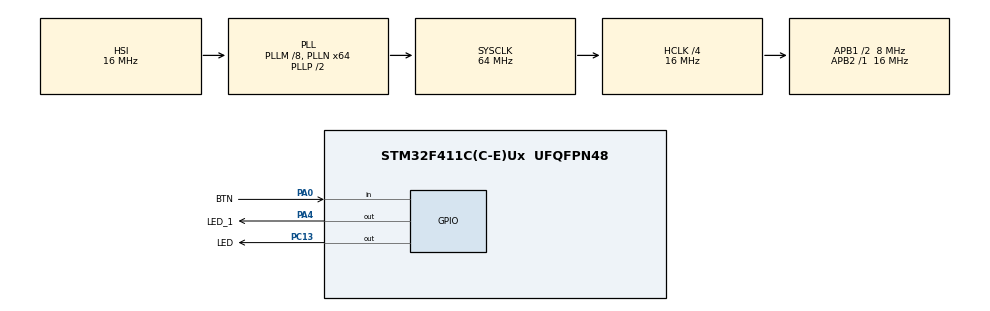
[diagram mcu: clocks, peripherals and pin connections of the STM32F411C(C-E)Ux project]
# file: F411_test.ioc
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Mcu.Family=STM32F4
Mcu.Name=STM32F411C(C-E)Ux
Mcu.Package=UFQFPN48
NVIC.PriorityGroup=NVIC_PRIORITYGROUP_4
PA0-WKUP.GPIO_Label=BTN
PA0-WKUP.GPIO_PuPd=GPIO_PULLUP
PA0-WKUP.Signal=GPIO_Input
PA4.GPIO_Label=LED_1
PA4.Signal=GPIO_Output
PC13-ANTI_TAMP.GPIO_Label=LED
PC13-ANTI_TAMP.PinState=GPIO_PIN_SET
PC13-ANTI_TAMP.Signal=GPIO_Output
ProjectManager.HeapSize=0x200
ProjectManager.StackSize=0x400
ProjectManager.TargetToolchain=STM32CubeIDE
RCC.48MHZClocksFreq_Value=32000000
RCC.AHBCLKDivider=RCC_SYSCLK_DIV4
RCC.AHBFreq_Value=16000000
RCC.APB1CLKDivider=RCC_HCLK_DIV2
RCC.APB1Freq_Value=8000000
RCC.APB1TimFreq_Value=16000000
RCC.APB2Freq_Value=16000000
RCC.APB2TimFreq_Value=16000000
RCC.CortexFreq_Value=16000000
RCC.HCLKFreq_Value=16000000
RCC.HSE_VALUE=25000000
RCC.HSI_VALUE=16000000
RCC.LSE_VALUE=32768
RCC.PLLM=8
RCC.PLLN=64
RCC.SYSCLKFreq_VALUE=64000000
RCC.SYSCLKSource=RCC_SYSCLKSOURCE_PLLCLK
RCC.VCOOutputFreq_Value=128000000
board=custom

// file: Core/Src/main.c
/* USER CODE BEGIN Header */
/**
  ******************************************************************************
  * @file           : main.c
  * @brief          : Main program body
  ******************************************************************************
  * @attention
  *
  * Copyright (c) 2026 STMicroelectronics.
  * All rights reserved.
  *
  * This software is licensed under terms that can be found in the LICENSE file
  * in the root directory of this software component.
  * If no LICENSE file comes with this software, it is provided AS-IS.
  *
  ******************************************************************************
  */
/* USER CODE END Header */
#include "main.h"

/* USER CODE BEGIN Includes */
#include <stdbool.h>
/* USER CODE END Includes */

/* USER CODE BEGIN PV */
static GPIO_PinState lastRaw;
static GPIO_PinState stable;
static uint32_t changedAt;
static bool state;
/* USER CODE END PV */

void SystemClock_Config(void);
static void MX_GPIO_Init(void);

int main(void)
{

  /* MCU Configuration--------------------------------------------------------*/

  /* Reset of all peripherals, Initializes the Flash interface and the Systick. */
  HAL_Init();

  /* Configure the system clock */
  SystemClock_Config();

  /* Initialize all configured peripherals */
  MX_GPIO_Init();
  /* USER CODE BEGIN 2 */
  lastRaw = HAL_GPIO_ReadPin(BTN_GPIO_Port, BTN_Pin);
  stable = lastRaw;
  changedAt = HAL_GetTick();
  state = false;
  /* USER CODE END 2 */

  /* Infinite loop */
  while (1)
  {

    /* USER CODE BEGIN 3 */

	  const uint32_t now = HAL_GetTick();
	      const GPIO_PinState raw = HAL_GPIO_ReadPin(BTN_GPIO_Port, BTN_Pin);
	      if (raw != lastRaw) {
	        lastRaw = raw;
	        changedAt = now;
	      }
	      if ((raw != stable) && ((uint32_t)(now - changedAt) >= 30U)) {
	        stable = raw;
	        if (stable == GPIO_PIN_RESET) {
	          state = !state;
	          /* LED_1_Pin - A4 */
	          HAL_GPIO_TogglePin(LED_1_GPIO_Port, LED_1_Pin);
	          HAL_GPIO_TogglePin(LED_GPIO_Port, LED_Pin);
	        }
	      }
	    }
  /* USER CODE END 3 */
}

void SystemClock_Config(void)
{
  RCC_OscInitTypeDef RCC_OscInitStruct = {0};
  RCC_ClkInitTypeDef RCC_ClkInitStruct = {0};

  /** Configure the main internal regulator output voltage
  */
  __HAL_RCC_PWR_CLK_ENABLE();
  __HAL_PWR_VOLTAGESCALING_CONFIG(PWR_REGULATOR_VOLTAGE_SCALE1);

  /** Initializes the RCC Oscillators according to the specified parameters
  * in the RCC_OscInitTypeDef structure.
  */
  RCC_OscInitStruct.OscillatorType = RCC_OSCILLATORTYPE_HSI;
  RCC_OscInitStruct.HSIState = RCC_HSI_ON;
  RCC_OscInitStruct.HSICalibrationValue = RCC_HSICALIBRATION_DEFAULT;
  RCC_OscInitStruct.PLL.PLLState = RCC_PLL_ON;
  RCC_OscInitStruct.PLL.PLLSource = RCC_PLLSOURCE_HSI;
  RCC_OscInitStruct.PLL.PLLM = 8;
  RCC_OscInitStruct.PLL.PLLN = 64;
  RCC_OscInitStruct.PLL.PLLP = RCC_PLLP_DIV2;
  RCC_OscInitStruct.PLL.PLLQ = 4;
  if (HAL_RCC_OscConfig(&RCC_OscInitStruct) != HAL_OK)
  {
    Error_Handler();
  }

  /** Initializes the CPU, AHB and APB buses clocks
  */
  RCC_ClkInitStruct.ClockType = RCC_CLOCKTYPE_HCLK|RCC_CLOCKTYPE_SYSCLK
                              |RCC_CLOCKTYPE_PCLK1|RCC_CLOCKTYPE_PCLK2;
  RCC_ClkInitStruct.SYSCLKSource = RCC_SYSCLKSOURCE_PLLCLK;
  RCC_ClkInitStruct.AHBCLKDivider = RCC_SYSCLK_DIV4;
  RCC_ClkInitStruct.APB1CLKDivider = RCC_HCLK_DIV2;
  RCC_ClkInitStruct.APB2CLKDivider = RCC_HCLK_DIV1;

  if (HAL_RCC_ClockConfig(&RCC_ClkInitStruct, FLASH_LATENCY_0) != HAL_OK)
  {
    Error_Handler();
  }
}

static void MX_GPIO_Init(void)
{
  GPIO_InitTypeDef GPIO_InitStruct = {0};

  /* GPIO Ports Clock Enable */
  __HAL_RCC_GPIOC_CLK_ENABLE();
  __HAL_RCC_GPIOA_CLK_ENABLE();

  /*Configure GPIO pin Output Level */
  HAL_GPIO_WritePin(LED_GPIO_Port, LED_Pin, GPIO_PIN_SET);

  /*Configure GPIO pin Output Level */
  HAL_GPIO_WritePin(LED_1_GPIO_Port, LED_1_Pin, GPIO_PIN_RESET);

  /*Configure GPIO pin : LED_Pin */
  GPIO_InitStruct.Pin = LED_Pin;
  GPIO_InitStruct.Mode = GPIO_MODE_OUTPUT_PP;
  GPIO_InitStruct.Pull = GPIO_NOPULL;
  GPIO_InitStruct.Speed = GPIO_SPEED_FREQ_LOW;
  HAL_GPIO_Init(LED_GPIO_Port, &GPIO_InitStruct);

  /*Configure GPIO pin : BTN_Pin */
  GPIO_InitStruct.Pin = BTN_Pin;
  GPIO_InitStruct.Mode = GPIO_MODE_INPUT;
  GPIO_InitStruct.Pull = GPIO_PULLUP;
  HAL_GPIO_Init(BTN_GPIO_Port, &GPIO_InitStruct);

  /*Configure GPIO pin : LED_1_Pin */
  GPIO_InitStruct.Pin = LED_1_Pin;
  GPIO_InitStruct.Mode = GPIO_MODE_OUTPUT_PP;
  GPIO_InitStruct.Pull = GPIO_NOPULL;
  GPIO_InitStruct.Speed = GPIO_SPEED_FREQ_LOW;
  HAL_GPIO_Init(LED_1_GPIO_Port, &GPIO_InitStruct);

}

void Error_Handler(void)
{
  __disable_irq();
  while (1)
  {
  }
}
